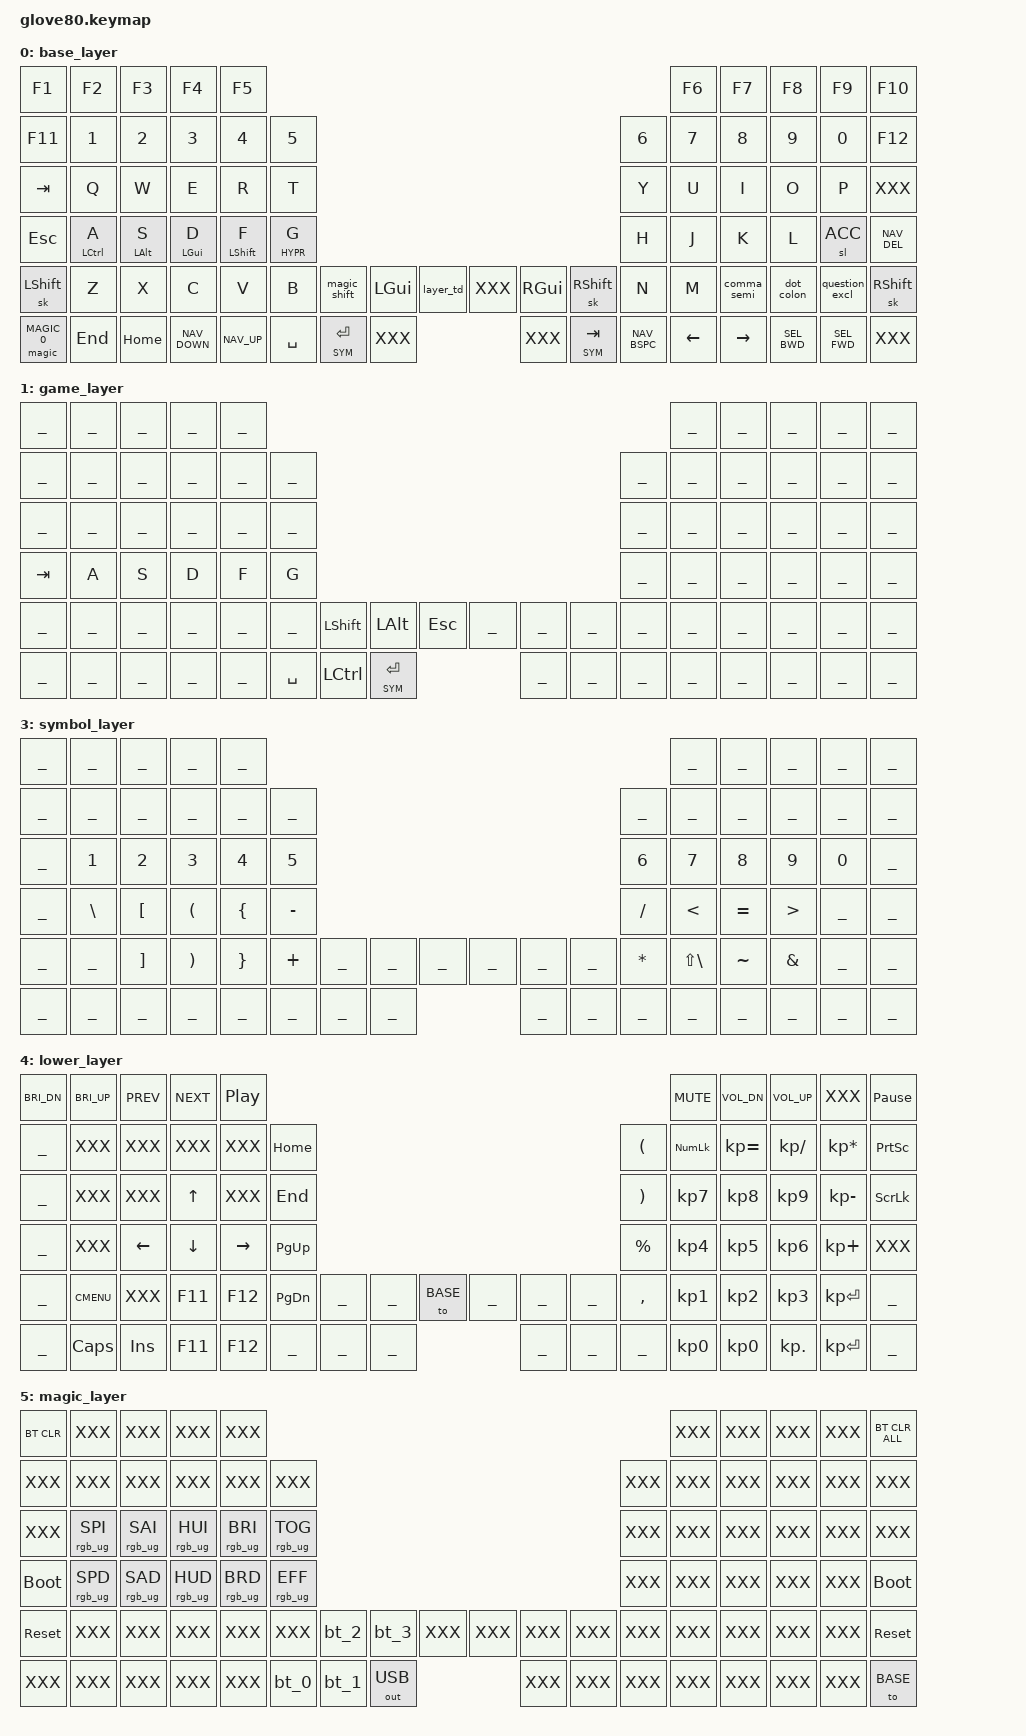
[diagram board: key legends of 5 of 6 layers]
/*
 * Copyright (c) 2020 The ZMK Contributors
 *
 * SPDX-License-Identifier: MIT
 */

#include <behaviors.dtsi>
#include <behaviors/num_word.dtsi>
#include <behaviors/unicode.dtsi>
#include <dt-bindings/zmk/keys.h>
#include <dt-bindings/zmk/bt.h>
#include <dt-bindings/zmk/ext_power.h>
#include <dt-bindings/zmk/outputs.h>
#include <dt-bindings/zmk/rgb.h>
#include <zmk-unicode/keys.h>

#include "constants.h"
#include "custom_behaviors.dtsi"
#include "macros.dtsi"
#include "combos.dtsi"

/ {
    keymap {
        compatible = "zmk,keymap";

        /* layer_template {
            bindings = <
            // ╭─────────────┬─────────────┬─────────────┬─────────────┬─────────────╮                                                                                                               ╭─────────────┬─────────────┬─────────────┬─────────────┬─────────────╮

            // ├─────────────┼─────────────┼─────────────┼─────────────┼─────────────┼─────────────╮                                                                                   ╭─────────────┼─────────────┼─────────────┼─────────────┼─────────────┼─────────────┤

            // ├─────────────┼─────────────┼─────────────┼─────────────┼─────────────┼─────────────┤                                                                                   ├─────────────┼─────────────┼─────────────┼─────────────┼─────────────┼─────────────┤

            // ├─────────────┼─────────────┼─────────────┼─────────────┼─────────────┼─────────────┤                                                                                   ├─────────────┼─────────────┼─────────────┼─────────────┼─────────────┼─────────────┤

            // ├─────────────┼─────────────┼─────────────┼─────────────┼─────────────┼─────────────┼─────────────┬─────────────┬─────────────┬─────────────┬─────────────┬─────────────┬─────────────┼─────────────┼─────────────┼─────────────┼─────────────┼─────────────┤

            // ├─────────────┼─────────────┼─────────────┼─────────────┼─────────────┼─────────────┤─────────────┼─────────────┼─────────────┼─────────────┼─────────────┼─────────────┤─────────────┼─────────────┼─────────────┼─────────────┼─────────────┼─────────────┤

            // ╰─────────────┴─────────────┴─────────────┴─────────────┴─────────────╯             ╰─────────────┴─────────────┴─────────────┴─────────────┴─────────────┴─────────────╯             ╰─────────────┴─────────────┴─────────────┴─────────────┴─────────────╯
            >;
        }; */

        base_layer {
            bindings = <
            // ╭─────────────┬─────────────┬─────────────┬─────────────┬─────────────╮                                                                                                               ╭─────────────┬─────────────┬─────────────┬─────────────┬─────────────╮
                 &kp F1        &kp F2        &kp F3        &kp F4        &kp F5                                                                                                                        &kp F6        &kp F7        &kp F8        &kp F9        &kp F10
            // ├─────────────┼─────────────┼─────────────┼─────────────┼─────────────┼─────────────╮                                                                                   ╭─────────────┼─────────────┼─────────────┼─────────────┼─────────────┼─────────────┤
                 &kp F11       &kp N1        &kp N2        &kp N3        &kp N4        &kp N5                                                                                            &kp N6        &kp N7        &kp N8        &kp N9        &kp N0        &kp F12
            // ├─────────────┼─────────────┼─────────────┼─────────────┼─────────────┼─────────────┤                                                                                   ├─────────────┼─────────────┼─────────────┼─────────────┼─────────────┼─────────────┤
                 &kp TAB       &kp Q         &kp W         &kp E         &kp R         &kp T                                                                                             &kp Y         &kp U         &kp I         &kp O         &kp P             XXX
            // ├─────────────┼─────────────┼─────────────┼─────────────┼─────────────┼─────────────┤                                                                                   ├─────────────┼─────────────┼─────────────┼─────────────┼─────────────┼─────────────┤
                 &kp ESC       &hml LCTRL A  &hml LALT S   &hml LGUI D   &hml LSHIFT F &hml HYPR G                                                                                       &kp H         &kp J         &kp K         &kp L         &sl ACC       NAV_DEL
            // ├─────────────┼─────────────┼─────────────┼─────────────┼─────────────┼─────────────┼─────────────┬─────────────┬─────────────┬─────────────┬─────────────┬─────────────┬─────────────┼─────────────┼─────────────┼─────────────┼─────────────┼─────────────┤
                 &sk LSHIFT    &kp Z         &kp X         &kp C         &kp V         &kp B         &magic_shift  &kp LGUI      &layer_td         XXX       &kp RGUI      &sk RSHIFT    &kp N         &kp M         &comma_semi   &dot_colon   &question_excl &sk RSHIFT
            // ├─────────────┼─────────────┼─────────────┼─────────────┼─────────────┼─────────────┤─────────────┼─────────────┼─────────────┼─────────────┼─────────────┼─────────────┤─────────────┼─────────────┼─────────────┼─────────────┼─────────────┼─────────────┤
                &magic MAGIC 0 &kp END       &kp HOME      NAV_DOWN      NAV_UP                      &kp SPACE     &lt SYM RET      XXX            XXX       &lt SYM TAB   NAV_BSPC                    &kp LEFT      &kp RIGHT     SEL_BWD       SEL_FWD           XXX
            // ╰─────────────┴─────────────┴─────────────┴─────────────┴─────────────╯             ╰─────────────┴─────────────┴─────────────┴─────────────┴─────────────┴─────────────╯             ╰─────────────┴─────────────┴─────────────┴─────────────┴─────────────╯
            >;
        };

        game_layer {
            bindings = <
            // ╭─────────────┬─────────────┬─────────────┬─────────────┬─────────────╮                                                                                                               ╭─────────────┬─────────────┬─────────────┬─────────────┬─────────────╮
                     ___           ___           ___           ___           ___                                                                                                                           ___           ___           ___           ___           ___
            // ├─────────────┼─────────────┼─────────────┼─────────────┼─────────────┼─────────────╮                                                                                   ╭─────────────┼─────────────┼─────────────┼─────────────┼─────────────┼─────────────┤
                     ___           ___           ___           ___           ___           ___                                                                                               ___           ___           ___           ___           ___           ___
            // ├─────────────┼─────────────┼─────────────┼─────────────┼─────────────┼─────────────┤                                                                                   ├─────────────┼─────────────┼─────────────┼─────────────┼─────────────┼─────────────┤
                     ___           ___           ___           ___           ___           ___                                                                                               ___           ___           ___           ___           ___           ___
            // ├─────────────┼─────────────┼─────────────┼─────────────┼─────────────┼─────────────┤                                                                                   ├─────────────┼─────────────┼─────────────┼─────────────┼─────────────┼─────────────┤
                  &kp TAB       &kp A         &kp S         &kp D         &kp F         &kp G                                                                                                 ___           ___           ___           ___           ___           ___
            // ├─────────────┼─────────────┼─────────────┼─────────────┼─────────────┼─────────────┼─────────────┬─────────────┬─────────────┬─────────────┬─────────────┬─────────────┬─────────────┼─────────────┼─────────────┼─────────────┼─────────────┼─────────────┤
                     ___           ___           ___           ___           ___           ___       &kp LSHIFT    &kp LALT      &kp ESC           ___           ___           ___           ___           ___           ___           ___           ___           ___
            // ├─────────────┼─────────────┼─────────────┼─────────────┼─────────────┼─────────────┤─────────────┼─────────────┼─────────────┼─────────────┼─────────────┼─────────────┤─────────────┼─────────────┼─────────────┼─────────────┼─────────────┼─────────────┤
                     ___           ___           ___           ___           ___                     &kp SPACE     &kp LCTRL     &lt SYM RET       ___           ___           ___                         ___           ___           ___           ___           ___
            // ╰─────────────┴─────────────┴─────────────┴─────────────┴─────────────╯             ╰─────────────┴─────────────┴─────────────┴─────────────┴─────────────┴─────────────╯             ╰─────────────┴─────────────┴─────────────┴─────────────┴─────────────╯
            >;
        };

        accent_layer {
            bindings = <
            // ╭─────────────┬─────────────┬─────────────┬─────────────┬─────────────╮                                                                                                               ╭─────────────┬─────────────┬─────────────┬─────────────┬─────────────╮
                     ___           ___           ___           ___           ___                                                                                                                           ___           ___           ___           ___           ___
            // ├─────────────┼─────────────┼─────────────┼─────────────┼─────────────┼─────────────╮                                                                                   ╭─────────────┼─────────────┼─────────────┼─────────────┼─────────────┼─────────────┤
                     ___           ___           ___           ___           ___           ___                                                                                               ___           ___           ___           ___           ___           ___
            // ├─────────────┼─────────────┼─────────────┼─────────────┼─────────────┼─────────────┤                                                                                   ├─────────────┼─────────────┼─────────────┼─────────────┼─────────────┼─────────────┤
                     ___   &uc UC_FR_A_CIRCUMFLEX  &kp CARET  &uc UC_FR_E_CIRCUMFLEX &kp DOLLAR    &kp PERCENT                                                                                       &uc UC_CURR_EURO &uc UC_FR_U_CIRCUMFLEX &uc UC_FR_I_CIRCUMFLEX &uc UC_FR_O_CIRCUMFLEX  ___           ___
            // ├─────────────┼─────────────┼─────────────┼─────────────┼─────────────┼─────────────┤                                                                                   ├─────────────┼─────────────┼─────────────┼─────────────┼─────────────┼─────────────┤
                     ___       &uc UC_FR_A_GRAVE   &uc UC_FR_E_ACUTE   &uc UC_FR_E_GRAVE   TUNDER       &kp MINUS                                                                                         TGRAVE        &uc UC_FR_U_GRAVE   &kp DQT       &kp SQT           ___           ___
            // ├─────────────┼─────────────┼─────────────┼─────────────┼─────────────┼─────────────┼─────────────┬─────────────┬─────────────┬─────────────┬─────────────┬─────────────┬─────────────┼─────────────┼─────────────┼─────────────┼─────────────┼─────────────┤
                     ___           ___           ___       &uc UC_FR_C_CEDILLA &uc UC_FR_E_DIAERESIS &kp AT          ___           ___           ___           ___           ___           ___       &kp HASH      &uc UC_FR_U_DIAERESIS &uc UC_FR_I_DIAERESIS ___           ___           ___
            // ├─────────────┼─────────────┼─────────────┼─────────────┼─────────────┼─────────────┤─────────────┼─────────────┼─────────────┼─────────────┼─────────────┼─────────────┤─────────────┼─────────────┼─────────────┼─────────────┼─────────────┼─────────────┤
                     ___           ___           ___           ___           ___                         ___           ___           ___           ___           ___           ___                         ___           ___           ___           ___           ___
            // ╰─────────────┴─────────────┴─────────────┴─────────────┴─────────────╯             ╰─────────────┴─────────────┴─────────────┴─────────────┴─────────────┴─────────────╯             ╰─────────────┴─────────────┴─────────────┴─────────────┴─────────────╯
            >;
        };

        symbol_layer {
            bindings = <
            // ╭─────────────┬─────────────┬─────────────┬─────────────┬─────────────╮                                                                                                               ╭─────────────┬─────────────┬─────────────┬─────────────┬─────────────╮
                     ___           ___           ___           ___           ___                                                                                                                           ___           ___           ___           ___           ___
            // ├─────────────┼─────────────┼─────────────┼─────────────┼─────────────┼─────────────╮                                                                                   ╭─────────────┼─────────────┼─────────────┼─────────────┼─────────────┼─────────────┤
                     ___           ___           ___           ___           ___           ___                                                                                               ___           ___           ___           ___           ___           ___
            // ├─────────────┼─────────────┼─────────────┼─────────────┼─────────────┼─────────────┤                                                                                   ├─────────────┼─────────────┼─────────────┼─────────────┼─────────────┼─────────────┤
                     ___       &kp N1        &kp N2        &kp N3        &kp N4        &kp N5                                                                                            &kp N6        &kp N7        &kp N8        &kp N9        &kp N0            ___
            // ├─────---─────┼─────────────┼─────────────┼─────────────┼─────────────┼─────────────┤                                                                                   ├─────────────┼─────────────┼─────────────┼─────────────┼─────────────┼─────────────┤
                     ___       &kp BSLH      &kp LBKT      &kp LPAR      &kp LBRC      &kp MINUS                                                                                         &kp SLASH     &kp LT        &kp EQUAL     &kp GT            ___           ___
            // ├─────---─────┼─────────────┼─────────────┼─────────────┼─────────────┼─────────────┼─────────────┬─────────────┬─────────────┬─────────────┬─────────────┬─────────────┬─────────────┼─────────────┼─────────────┼─────────────┼─────────────┼─────────────┤
                     ___           ___       &kp RBKT      &kp RPAR      &kp RBRC      &kp PLUS         ___           ___           ___           ___           ___           ___        &kp STAR      &kp LS(BSLH)  &kp TILDE     &kp AMPS          ___           ___
            // ├─────────────┼─────────────┼─────────────┼─────────────┼─────────────┼─────────────┤─────────────┼─────────────┼─────────────┼─────────────┼─────────────┼─────────────┤─────────────┼─────────────┼─────────────┼─────────────┼─────────────┼─────────────┤
                     ___           ___           ___           ___           ___                        ___           ___           ___           ___           ___           ___                         ___           ___           ___            ___           ___
            // ╰─────────────┴─────────────┴─────────────┴─────────────┴─────────────╯             ╰─────────────┴─────────────┴─────────────┴─────────────┴─────────────┴─────────────╯             ╰─────────────┴─────────────┴─────────────┴─────────────┴─────────────╯
            >;
        };

        lower_layer {
            bindings = <
            // ╭─────────────┬─────────────┬─────────────┬─────────────┬─────────────╮                                                                                                               ╭─────────────┬─────────────┬─────────────┬─────────────┬─────────────╮
                 &kp C_BRI_DN  &kp C_BRI_UP  &kp C_PREV    &kp C_NEXT    &kp C_PP                                                                                                                      &kp C_MUTE    &kp C_VOL_DN  &kp C_VOL_UP      XXX     &kp PAUSE_BREAK
            // ├─────────────┼─────────────┼─────────────┼─────────────┼─────────────┼─────────────╮                                                                                   ╭─────────────┼─────────────┼─────────────┼─────────────┼─────────────┼─────────────┤
                     ___           XXX           XXX           XXX           XXX       &kp HOME                                                                                          &kp LPAR      &kp KP_NUM    &kp KP_EQUAL  &kp KP_DIVIDE &kp KP_MULTIPLY &kp PSCRN
            // ├─────────────┼─────────────┼─────────────┼─────────────┼─────────────┼─────────────┤                                                                                   ├─────────────┼─────────────┼─────────────┼─────────────┼─────────────┼─────────────┤
                     ___           XXX           XXX       &kp UP            XXX       &kp END                                                                                           &kp RPAR      &kp KP_N7     &kp KP_N8     &kp KP_N9     &kp KP_MINUS  &kp SLCK
            // ├─────────────┼─────────────┼─────────────┼─────────────┼─────────────┼─────────────┤                                                                                   ├─────────────┼─────────────┼─────────────┼─────────────┼─────────────┼─────────────┤
                     ___           XXX       &kp LEFT      &kp DOWN      &kp RIGHT     &kp PG_UP                                                                                         &kp PRCNT     &kp KP_N4     &kp KP_N5     &kp KP_N6     &kp KP_PLUS       XXX
            // ├─────────────┼─────────────┼─────────────┼─────────────┼─────────────┼─────────────┼─────────────┬─────────────┬─────────────┬─────────────┬─────────────┬─────────────┬─────────────┼─────────────┼─────────────┼─────────────┼─────────────┼─────────────┤
                     ___       &kp K_CMENU       XXX       &kp F11       &kp F12       &kp PG_DN         ___           ___       &to BASE          ___           ___           ___       &kp COMMA     &kp KP_N1     &kp KP_N2     &kp KP_N3     &kp KP_ENTER      ___
            // ├─────────────┼─────────────┼─────────────┼─────────────┼─────────────┼─────────────┤─────────────┼─────────────┼─────────────┼─────────────┼─────────────┼─────────────┤─────────────┼─────────────┼─────────────┼─────────────┼─────────────┼─────────────┤
                     ___       &kp CAPS      &kp INS       &kp F11       &kp F12                         ___           ___           ___           ___           ___           ___                     &kp KP_N0     &kp KP_N0     &kp KP_DOT    &kp KP_ENTER      ___
            // ╰─────────────┴─────────────┴─────────────┴─────────────┴─────────────╯             ╰─────────────┴─────────────┴─────────────┴─────────────┴─────────────┴─────────────╯             ╰─────────────┴─────────────┴─────────────┴─────────────┴─────────────╯
            >;
        };

        magic_layer {
            bindings = <
            // ╭─────────────┬─────────────┬─────────────┬─────────────┬─────────────╮                                                                                                               ╭─────────────┬─────────────┬─────────────┬─────────────┬─────────────╮
                 &bt BT_CLR        XXX           XXX           XXX           XXX                                                                                                                           XXX           XXX           XXX           XXX      &bt BT_CLR_ALL
            // ├─────────────┼─────────────┼─────────────┼─────────────┼─────────────┼─────────────╮                                                                                   ╭─────────────┼─────────────┼─────────────┼─────────────┼─────────────┼─────────────┤
                     XXX           XXX           XXX           XXX           XXX           XXX                                                                                               XXX           XXX           XXX           XXX           XXX           XXX
            // ├─────────────┼─────────────┼─────────────┼─────────────┼─────────────┼─────────────┤                                                                                   ├─────────────┼─────────────┼─────────────┼─────────────┼─────────────┼─────────────┤
                     XXX     &rgb_ug RGB_SPI &rgb_ug RGB_SAI &rgb_ug RGB_HUI &rgb_ug RGB_BRI &rgb_ug RGB_TOG                                                                             XXX           XXX           XXX           XXX           XXX           XXX
            // ├─────────────┼─────────────┼─────────────┼─────────────┼─────────────┼─────────────┤                                                                                   ├─────────────┼─────────────┼─────────────┼─────────────┼─────────────┼─────────────┤
                 &bootloader   &rgb_ug RGB_SPD &rgb_ug RGB_SAD &rgb_ug RGB_HUD &rgb_ug RGB_BRD &rgb_ug RGB_EFF                                                                               XXX           XXX           XXX           XXX           XXX       &bootloader
            // ├─────────────┼─────────────┼─────────────┼─────────────┼─────────────┼─────────────┼─────────────┬─────────────┬─────────────┬─────────────┬─────────────┬─────────────┬─────────────┼─────────────┼─────────────┼─────────────┼─────────────┼─────────────┤
                 &sys_reset        XXX           XXX           XXX           XXX           XXX       &bt_2         &bt_3             XXX           XXX           XXX           XXX           XXX           XXX           XXX           XXX           XXX       &sys_reset
            // ├─────────────┼─────────────┼─────────────┼─────────────┼─────────────┼─────────────┤─────────────┼─────────────┼─────────────┼─────────────┼─────────────┼─────────────┤─────────────┼─────────────┼─────────────┼─────────────┼─────────────┼─────────────┤
                     XXX           XXX           XXX           XXX           XXX                     &bt_0         &bt_1         &out OUT_USB      XXX           XXX           XXX                         XXX           XXX           XXX           XXX       &to BASE
            // ╰─────────────┴─────────────┴─────────────┴─────────────┴─────────────╯             ╰─────────────┴─────────────┴─────────────┴─────────────┴─────────────┴─────────────╯             ╰─────────────┴─────────────┴─────────────┴─────────────┴─────────────╯
            >;
        };
    };
};
